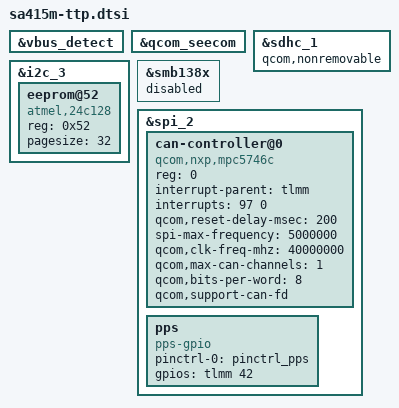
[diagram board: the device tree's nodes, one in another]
#include "sa415m-mtp.dtsi"

&vbus_detect {
	status = "okay";
};

&qcom_seecom {
	status = "okay";
};

&sdhc_1 {
	qcom,nonremovable;
};

&i2c_3 {
	eeprom@52 {
		compatible = "atmel,24c128";
		reg = <0x52>;
		pagesize = <32>;
	};
};

&smb138x {
	status = "disabled";
};

&spi_2 {
	status = "okay";

	can-controller@0 {
		compatible = "qcom,nxp,mpc5746c";
		reg = <0>;
		interrupt-parent = <&tlmm>;
		interrupts = <97 0>;
		qcom,reset-delay-msec = <200>;
		spi-max-frequency = <5000000>;
		qcom,clk-freq-mhz = <40000000>;
		qcom,max-can-channels = <1>;
		qcom,bits-per-word = <8>;
		qcom,support-can-fd;
	};
	pps {
		compatible = "pps-gpio";
		pinctrl-names = "default";
		pinctrl-0 = <&pinctrl_pps>;
		gpios = <&tlmm 42 GPIO_ACTIVE_HIGH>;
		status = "okay";
	};
};
